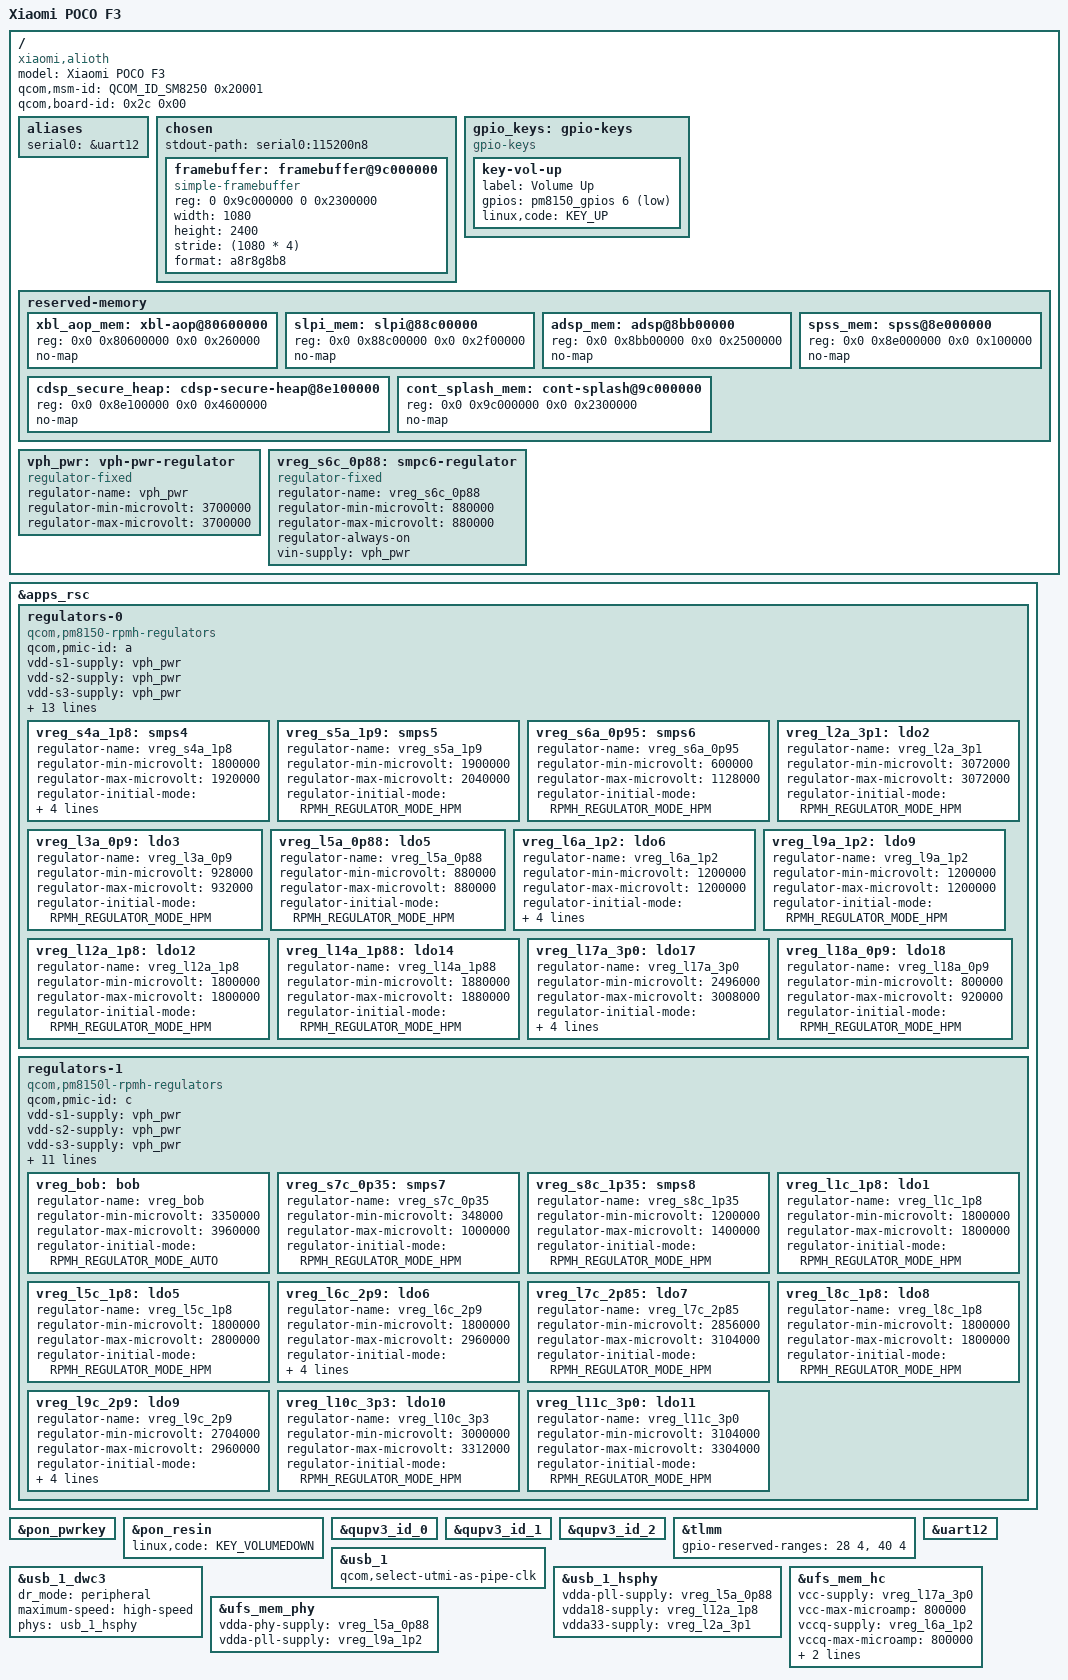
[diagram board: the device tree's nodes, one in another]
/dts-v1/;

#include <dt-bindings/arm/qcom,ids.h>
#include <dt-bindings/regulator/qcom,rpmh-regulator.h>

#include "sm8250.dtsi"
#include "pm8150.dtsi"
#include "pm8150b.dtsi"
#include "pm8150l.dtsi"

/*
* Delete following upstream (sm8250.dtsi) reserved
* memory mappings which are different on this device.
*/
/delete-node/ &adsp_mem;
/delete-node/ &cdsp_secure_heap;
/delete-node/ &slpi_mem;
/delete-node/ &spss_mem;
/delete-node/ &xbl_aop_mem;

/ {
	model = "Xiaomi POCO F3";
	compatible = "xiaomi,alioth", "qcom,sm8250";

    qcom,msm-id = <QCOM_ID_SM8250 0x20001>;
    qcom,board-id = <0x2c 0x00>;

	aliases {
		serial0 = &uart12;
	};

	chosen {
		#address-cells = <2>;
		#size-cells = <2>;
		ranges;
        
		stdout-path = "serial0:115200n8";

        framebuffer: framebuffer@9c000000 {
            compatible = "simple-framebuffer";
            reg = <0 0x9c000000 0 0x2300000>;
            width = <1080>;
            height = <2400>;
            stride = <(1080 * 4)>;
            format = "a8r8g8b8";
        };
	};

    gpio_keys: gpio-keys {
        compatible = "gpio-keys";

        key-vol-up {
            label = "Volume Up";
            gpios = <&pm8150_gpios 6 GPIO_ACTIVE_LOW>;
            linux,code = <KEY_UP>;
        };
    };

    reserved-memory {
		#address-cells = <2>;
		#size-cells = <2>;

		xbl_aop_mem: xbl-aop@80600000 {
			reg = <0x0 0x80600000 0x0 0x260000>;
			no-map;
		};

		slpi_mem: slpi@88c00000 {
			reg = <0x0 0x88c00000 0x0 0x2f00000>;
			no-map;
		};

		adsp_mem: adsp@8bb00000 {
			reg = <0x0 0x8bb00000 0x0 0x2500000>;
			no-map;
		};

		spss_mem: spss@8e000000 {
			reg = <0x0 0x8e000000 0x0 0x100000>;
			no-map;
		};

		cdsp_secure_heap: cdsp-secure-heap@8e100000 {
			reg = <0x0 0x8e100000 0x0 0x4600000>;
			no-map;
		};

		cont_splash_mem: cont-splash@9c000000 {
			reg = <0x0 0x9c000000 0x0 0x2300000>;
			no-map;
		};
    };

    vph_pwr: vph-pwr-regulator {
        compatible = "regulator-fixed";
        regulator-name = "vph_pwr";
        regulator-min-microvolt = <3700000>;
        regulator-max-microvolt = <3700000>;
    };

    vreg_s6c_0p88: smpc6-regulator {
        compatible = "regulator-fixed";
        regulator-name = "vreg_s6c_0p88";
        regulator-min-microvolt = <880000>;
        regulator-max-microvolt = <880000>;
        regulator-always-on;
        vin-supply = <&vph_pwr>;
    };
};

&apps_rsc {
    regulators-0 {
        compatible = "qcom,pm8150-rpmh-regulators";
        qcom,pmic-id = "a";

        vdd-s1-supply = <&vph_pwr>;
        vdd-s2-supply = <&vph_pwr>;
        vdd-s3-supply = <&vph_pwr>;
        vdd-s4-supply = <&vph_pwr>;
        vdd-s5-supply = <&vph_pwr>;
        vdd-s6-supply = <&vph_pwr>;
        vdd-s7-supply = <&vph_pwr>;
        vdd-s8-supply = <&vph_pwr>;
        vdd-s9-supply = <&vph_pwr>;
        vdd-s10-supply = <&vph_pwr>;
        vdd-l1-l8-l11-supply = <&vreg_s6c_0p88>;
        vdd-l2-l10-supply = <&vreg_bob>;
        vdd-l3-l4-l5-l18-supply = <&vreg_s6a_0p95>;
        vdd-l6-l9-supply = <&vreg_s8c_1p35>;
        vdd-l7-l12-l14-l15-supply = <&vreg_s5a_1p9>;
        vdd-l13-l16-l17-supply = <&vreg_bob>;

        /* (S1+S2+S3) - cx.lvl (ARC) */

        vreg_s4a_1p8: smps4 {
            regulator-name = "vreg_s4a_1p8";
            regulator-min-microvolt = <1800000>;
            regulator-max-microvolt = <1920000>;
            regulator-initial-mode = <RPMH_REGULATOR_MODE_HPM>;
            regulator-allow-set-load;
            regulator-allowed-modes = <RPMH_REGULATOR_MODE_LPM
                        RPMH_REGULATOR_MODE_HPM>;
        };

        vreg_s5a_1p9: smps5 {
            regulator-name = "vreg_s5a_1p9";
            regulator-min-microvolt = <1900000>;
            regulator-max-microvolt = <2040000>;
            regulator-initial-mode = <RPMH_REGULATOR_MODE_HPM>;
        };

        vreg_s6a_0p95: smps6 {
            regulator-name = "vreg_s6a_0p95";
            regulator-min-microvolt = <600000>;
            regulator-max-microvolt = <1128000>;
            regulator-initial-mode = <RPMH_REGULATOR_MODE_HPM>;
        };

        vreg_l2a_3p1: ldo2 {
            regulator-name = "vreg_l2a_3p1";
            regulator-min-microvolt = <3072000>;
            regulator-max-microvolt = <3072000>;
            regulator-initial-mode = <RPMH_REGULATOR_MODE_HPM>;
        };

        vreg_l3a_0p9: ldo3 {
            regulator-name = "vreg_l3a_0p9";
            regulator-min-microvolt = <928000>;
            regulator-max-microvolt = <932000>;
            regulator-initial-mode = <RPMH_REGULATOR_MODE_HPM>;
        };

        /* L4 - lmx.lvl (ARC) */

        vreg_l5a_0p88: ldo5 {
            regulator-name = "vreg_l5a_0p88";
            regulator-min-microvolt = <880000>;
            regulator-max-microvolt = <880000>;
            regulator-initial-mode = <RPMH_REGULATOR_MODE_HPM>;
        };

        vreg_l6a_1p2: ldo6 {
            regulator-name = "vreg_l6a_1p2";
            regulator-min-microvolt = <1200000>;
            regulator-max-microvolt = <1200000>;
            regulator-initial-mode = <RPMH_REGULATOR_MODE_HPM>;
            regulator-allow-set-load;
            regulator-allowed-modes = <RPMH_REGULATOR_MODE_LPM
                        RPMH_REGULATOR_MODE_HPM>;
        };

        /* L7 is unused. */

        vreg_l9a_1p2: ldo9 {
            regulator-name = "vreg_l9a_1p2";
            regulator-min-microvolt = <1200000>;
            regulator-max-microvolt = <1200000>;
            regulator-initial-mode = <RPMH_REGULATOR_MODE_HPM>;
        };

        /* L10 is unused, L11 - lcx.lvl (ARC) */

        vreg_l12a_1p8: ldo12 {
            regulator-name = "vreg_l12a_1p8";
            regulator-min-microvolt = <1800000>;
            regulator-max-microvolt = <1800000>;
            regulator-initial-mode = <RPMH_REGULATOR_MODE_HPM>;
        };

        /* L13 is unused. */

        vreg_l14a_1p88: ldo14 {
            regulator-name = "vreg_l14a_1p88";
            regulator-min-microvolt = <1880000>;
            regulator-max-microvolt = <1880000>;
            regulator-initial-mode = <RPMH_REGULATOR_MODE_HPM>;
        };

        /* L15 & L16 are unused. */

        vreg_l17a_3p0: ldo17 {
            regulator-name = "vreg_l17a_3p0";
            regulator-min-microvolt = <2496000>;
            regulator-max-microvolt = <3008000>;
            regulator-initial-mode = <RPMH_REGULATOR_MODE_HPM>;
            regulator-allow-set-load;
            regulator-allowed-modes = <RPMH_REGULATOR_MODE_LPM
                        RPMH_REGULATOR_MODE_HPM>;
        };

        vreg_l18a_0p9: ldo18 {
            regulator-name = "vreg_l18a_0p9";
            regulator-min-microvolt = <800000>;
            regulator-max-microvolt = <920000>;
            regulator-initial-mode = <RPMH_REGULATOR_MODE_HPM>;
        };
    };

    regulators-1 {
        compatible = "qcom,pm8150l-rpmh-regulators";
        qcom,pmic-id = "c";

        vdd-s1-supply = <&vph_pwr>;
        vdd-s2-supply = <&vph_pwr>;
        vdd-s3-supply = <&vph_pwr>;
        vdd-s4-supply = <&vph_pwr>;
        vdd-s5-supply = <&vph_pwr>;
        vdd-s6-supply = <&vph_pwr>;
        vdd-s7-supply = <&vph_pwr>;
        vdd-s8-supply = <&vph_pwr>;
        vdd-l1-l8-supply = <&vreg_s4a_1p8>;
        vdd-l2-l3-supply = <&vreg_s8c_1p35>;
        vdd-l4-l5-l6-supply = <&vreg_bob>;
        vdd-l7-l11-supply = <&vreg_bob>;
        vdd-l9-l10-supply = <&vreg_bob>;
        vdd-bob-supply = <&vph_pwr>;

        vreg_bob: bob {
            regulator-name = "vreg_bob";
            regulator-min-microvolt = <3350000>;
            regulator-max-microvolt = <3960000>;
            regulator-initial-mode = <RPMH_REGULATOR_MODE_AUTO>;
        };

        /*
        * S1-S6 are ARCs:
        * (S1+S2) - gfx.lvl,
        * S3 - mx.lvl,
        * (S4+S5) - mmcx.lvl,
        * S6 - ebi.lvl
        */

        vreg_s7c_0p35: smps7 {
            regulator-name = "vreg_s7c_0p35";
            regulator-min-microvolt = <348000>;
            regulator-max-microvolt = <1000000>;
            regulator-initial-mode = <RPMH_REGULATOR_MODE_HPM>;
        };

        vreg_s8c_1p35: smps8 {
            regulator-name = "vreg_s8c_1p35";
            regulator-min-microvolt = <1200000>;
            regulator-max-microvolt = <1400000>;
            regulator-initial-mode = <RPMH_REGULATOR_MODE_HPM>;
        };

        vreg_l1c_1p8: ldo1 {
            regulator-name = "vreg_l1c_1p8";
            regulator-min-microvolt = <1800000>;
            regulator-max-microvolt = <1800000>;
            regulator-initial-mode = <RPMH_REGULATOR_MODE_HPM>;
        };

        /* L2-4 are unused. */

        vreg_l5c_1p8: ldo5 {
            regulator-name = "vreg_l5c_1p8";
            regulator-min-microvolt = <1800000>;
            regulator-max-microvolt = <2800000>;
            regulator-initial-mode = <RPMH_REGULATOR_MODE_HPM>;
        };

        vreg_l6c_2p9: ldo6 {
            regulator-name = "vreg_l6c_2p9";
            regulator-min-microvolt = <1800000>;
            regulator-max-microvolt = <2960000>;
            regulator-initial-mode = <RPMH_REGULATOR_MODE_HPM>;
            regulator-allow-set-load;
            regulator-allowed-modes = <RPMH_REGULATOR_MODE_LPM
                        RPMH_REGULATOR_MODE_HPM>;
        };

        vreg_l7c_2p85: ldo7 {
            regulator-name = "vreg_l7c_2p85";
            regulator-min-microvolt = <2856000>;
            regulator-max-microvolt = <3104000>;
            regulator-initial-mode = <RPMH_REGULATOR_MODE_HPM>;
        };

        vreg_l8c_1p8: ldo8 {
            regulator-name = "vreg_l8c_1p8";
            regulator-min-microvolt = <1800000>;
            regulator-max-microvolt = <1800000>;
            regulator-initial-mode = <RPMH_REGULATOR_MODE_HPM>;
        };

        vreg_l9c_2p9: ldo9 {
            regulator-name = "vreg_l9c_2p9";
            regulator-min-microvolt = <2704000>;
            regulator-max-microvolt = <2960000>;
            regulator-initial-mode = <RPMH_REGULATOR_MODE_HPM>;
            regulator-allow-set-load;
            regulator-allowed-modes = <RPMH_REGULATOR_MODE_LPM
                        RPMH_REGULATOR_MODE_HPM>;
        };

        vreg_l10c_3p3: ldo10 {
            regulator-name = "vreg_l10c_3p3";
            regulator-min-microvolt = <3000000>;
            regulator-max-microvolt = <3312000>;
            regulator-initial-mode = <RPMH_REGULATOR_MODE_HPM>;
        };

        vreg_l11c_3p0: ldo11 {
            regulator-name = "vreg_l11c_3p0";
            regulator-min-microvolt = <3104000>;
            regulator-max-microvolt = <3304000>;
            regulator-initial-mode = <RPMH_REGULATOR_MODE_HPM>;
        };
    };
};

&pon_pwrkey {
    status = "okay";
};

&pon_resin {
    linux,code = <KEY_VOLUMEDOWN>;
    status = "okay";
};

&qupv3_id_0 {
	status = "okay";
};

&qupv3_id_1 {
	status = "okay";
};

&qupv3_id_2 {
	status = "okay";
};

&tlmm {
	gpio-reserved-ranges = <28 4>, <40 4>;
};

&uart12 {
	status = "okay";
};

&usb_1 {
	/* USB 2.0 only */
	qcom,select-utmi-as-pipe-clk;
	status = "okay";
};

&usb_1_dwc3 {
	dr_mode = "peripheral";
	maximum-speed = "high-speed";
	/* Remove USB3 phy */
	phys = <&usb_1_hsphy>;
	phy-names = "usb2-phy";
};

&usb_1_hsphy {
	vdda-pll-supply = <&vreg_l5a_0p88>;
	vdda18-supply = <&vreg_l12a_1p8>;
	vdda33-supply = <&vreg_l2a_3p1>;
	status = "okay";
};

&ufs_mem_hc {
    vcc-supply = <&vreg_l17a_3p0>;
    vcc-max-microamp = <800000>;
    vccq-supply = <&vreg_l6a_1p2>;
    vccq-max-microamp = <800000>;
    vccq2-supply = <&vreg_s4a_1p8>;
    vccq2-max-microamp = <800000>;
    status = "okay";
};

&ufs_mem_phy {
    vdda-phy-supply = <&vreg_l5a_0p88>;
    vdda-pll-supply = <&vreg_l9a_1p2>;
    status = "okay";
};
